VERSION ""

NS_ :

BS_:

BU_: TBox

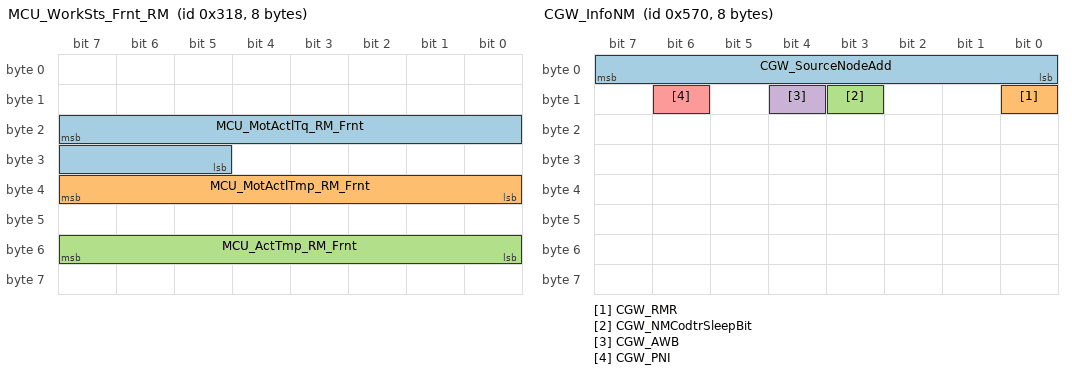
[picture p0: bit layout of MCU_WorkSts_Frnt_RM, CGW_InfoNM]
BO_ 792 MCU_WorkSts_Frnt_RM: 8 CGW
 SG_ MCU_MotActlTq_RM_Frnt : 23|11@0+ (0.5,-500) [-500|500] "Nm" TBox
 SG_ MCU_MotActlTmp_RM_Frnt : 39|8@0+ (1,-40) [-40|214] "degree C" TBox
 SG_ MCU_ActTmp_RM_Frnt : 55|8@0+ (1,-40) [-40|214] "degree C" TBox

BO_ 1392 CGW_InfoNM: 8 CGW
 SG_ CGW_SourceNodeAdd : 7|8@0+ (1,0) [112|112] "" TBox,HU,AMP
 SG_ CGW_RMR : 8|1@0+ (1,0) [0|1] "" TBox,HU,AMP
 SG_ CGW_NMCodtrSleepBit : 11|1@0+ (1,0) [0|1] "" TBox,HU,AMP
 SG_ CGW_AWB : 12|1@0+ (1,0) [0|1] "" TBox,HU,AMP
 SG_ CGW_PNI : 14|1@0+ (1,0) [0|1] "" TBox,HU,AMP

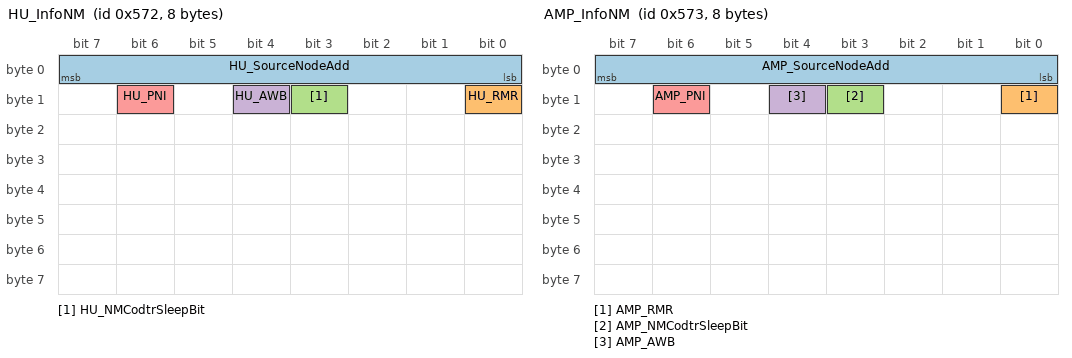
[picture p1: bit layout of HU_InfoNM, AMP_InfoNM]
BO_ 1394 HU_InfoNM: 8 HU
 SG_ HU_SourceNodeAdd : 7|8@0+ (1,0) [114|114] "" TBox,AMP,CGW
 SG_ HU_RMR : 8|1@0+ (1,0) [0|1] "" TBox,AMP,CGW
 SG_ HU_NMCodtrSleepBit : 11|1@0+ (1,0) [0|1] "" TBox,AMP,CGW
 SG_ HU_AWB : 12|1@0+ (1,0) [0|1] "" TBox,AMP,CGW
 SG_ HU_PNI : 14|1@0+ (1,0) [0|1] "" TBox,AMP,CGW

BO_ 1395 AMP_InfoNM: 8 AMP
 SG_ AMP_SourceNodeAdd : 7|8@0+ (1,0) [115|115] "" TBox,HU,CGW
 SG_ AMP_RMR : 8|1@0+ (1,0) [0|1] "" TBox,HU,CGW
 SG_ AMP_NMCodtrSleepBit : 11|1@0+ (1,0) [0|1] "" TBox,HU,CGW
 SG_ AMP_AWB : 12|1@0+ (1,0) [0|1] "" TBox,HU,CGW
 SG_ AMP_PNI : 14|1@0+ (1,0) [0|1] "" TBox,HU,CGW

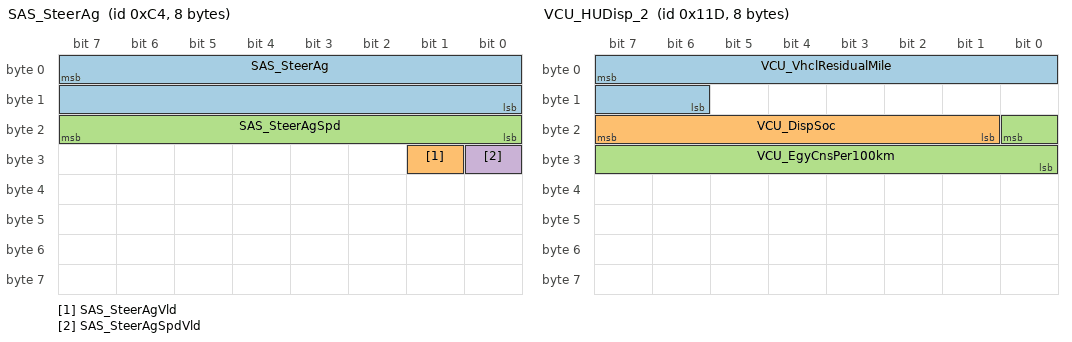
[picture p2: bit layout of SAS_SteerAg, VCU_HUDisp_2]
BO_ 196 SAS_SteerAg: 8 CGW
 SG_ SAS_SteerAg : 7|16@0+ (0.0625,-2048) [-720|720] "Deg" TBox,HU
 SG_ SAS_SteerAgVld : 25|1@0+ (1,0) [0|1] "" TBox,HU
 SG_ SAS_SteerAgSpd : 23|8@0+ (4,0) [0|1016] "Deg/s" TBox
 SG_ SAS_SteerAgSpdVld : 24|1@0+ (1,0) [0|1] "" TBox

BO_ 284 VCU_HUDisp_1: 8 CGW
 SG_ VCU_ChrgStsIndcr : 7|1@0+ (1,0) [0|1] "" TBox,HU,AMP
 SG_ VCU_ChrgConnectIndcr : 6|1@0+ (1,0) [0|1] "" TBox,HU

BO_ 285 VCU_HUDisp_2: 8 CGW
 SG_ VCU_VhclResidualMile : 7|10@0+ (1,0) [0|800] "km" TBox,HU
 SG_ VCU_DispSoc : 23|7@0+ (1,0) [0|100] "%" TBox,HU
 SG_ VCU_EgyCnsPer100km : 16|9@0+ (0.1,0) [0|30] "kwh/100km" TBox,HU

CM_ SG_ 1394 HU_SourceNodeAdd "Source Node Address
原节点地址";
CM_ SG_ 1394 HU_RMR "Repeat message request
重复报文请求";
CM_ SG_ 1394 HU_NMCodtrSleepBit "NM Coordinator Sleep Bit
网络管理协调睡眠指示位";
CM_ SG_ 1394 HU_AWB "Active wakeup bit
主动唤醒指示位";
CM_ SG_ 1394 HU_PNI "Partial netwark information bit 
局部网络指示位";
CM_ SG_ 1395 AMP_SourceNodeAdd "Source Node Address
原节点地址";
CM_ SG_ 1395 AMP_RMR "Repeat message request
重复报文请求";
CM_ SG_ 1395 AMP_NMCodtrSleepBit "NM Coordinator Sleep Bit
网络管理协调睡眠指示位";
CM_ SG_ 1395 AMP_AWB "Active wakeup bit
主动唤醒指示位";
CM_ SG_ 1395 AMP_PNI "Partial netwark information bit 
局部网络指示位";
CM_ SG_ 1392 CGW_SourceNodeAdd "Source Node Address
原节点地址";
CM_ SG_ 1392 CGW_RMR "Repeat message request
重复报文请求";
CM_ SG_ 1392 CGW_NMCodtrSleepBit "NM Coordinator Sleep Bit
网络管理协调睡眠指示位";
CM_ SG_ 1392 CGW_AWB "Active wakeup bit
主动唤醒指示位";
CM_ SG_ 1392 CGW_PNI "Partial netwark information bit 
局部网络指示位";
CM_ SG_ 284 VCU_ChrgStsIndcr "Charge status indicator
充电状态指示";
CM_ SG_ 284 VCU_ChrgConnectIndcr "Charge connect indicator
充电链接指示";
CM_ SG_ 285 VCU_VhclResidualMile "Vehicle residual mileage
剩余续驶里程";
CM_ SG_ 285 VCU_DispSoc "SOC used for display
动力电池剩余SOC";
CM_ SG_ 285 VCU_EgyCnsPer100km "Energy consume per 100km
平均百公里能耗";
CM_ SG_ 792 MCU_MotActlTq_RM_Frnt "Motor actual torque
电机实际扭矩";
CM_ SG_ 792 MCU_MotActlTmp_RM_Frnt "Actual temperature of motor
电机实际温度";
CM_ SG_ 792 MCU_ActTmp_RM_Frnt "MCU actual temperature
电机控制器实际温度";
CM_ SG_ 196 SAS_SteerAg "Steering Angle value
方向盘转向角";
CM_ SG_ 196 SAS_SteerAgVld "Steering Angle Valid Check
方向盘转向角有效位";
CM_ SG_ 196 SAS_SteerAgSpd "Steering  Angle Speed value
方向盘转角速度";
CM_ SG_ 196 SAS_SteerAgSpdVld "Steering Angle Speed valid Check
方向盘转向角速度有效位";

BA_DEF_ BO_  "NmMessage" ENUM "No","Yes";
BA_DEF_ BO_  "GenMsgSendType" ENUM  "Cycle","NoSendType","IfActive";
BA_DEF_ BO_  "GenMsgCycleTime" INT 0 0;
BA_DEF_ SG_  "GenSigSendType" ENUM  "Cycle","OnChange","OnWrite","IfActive","OnChangeWithRepetition","OnWriteWithRepetition","IfActiveWithRepetition";
BA_DEF_ SG_  "GenSigStartValue" INT 0 0;
BA_DEF_ BO_  "GenMsgCycleTimeFast" INT 0 0;
BA_DEF_ BO_  "GenMsgNrOfRepetition" INT 0 0;
BA_DEF_ BO_  "GenMsgDelayTime" INT 0 0;
BA_DEF_ BO_  "VFrameFormat" ENUM  "StandardCAN","ExtendedCAN","reserved","reserved","reserved","reserved","reserved","reserved","reserved","reserved","reserved","reserved","reserved","reserved","StandardCAN_FD","ExtendedCAN_FD";

BA_DEF_DEF_  "NmMessage" "No";
BA_DEF_DEF_  "GenMsgSendType" "Cycle";
BA_DEF_DEF_  "GenMsgCycleTime" 0;
BA_DEF_DEF_  "GenSigSendType" "Cycle";
BA_DEF_DEF_  "GenSigStartValue" 0;
BA_DEF_DEF_  "GenMsgCycleTimeFast" 0;
BA_DEF_DEF_  "GenMsgNrOfRepetition" 0;
BA_DEF_DEF_  "GenMsgDelayTime" 0;
BA_DEF_DEF_  "VFrameFormat" "StandardCAN";
BA_ "GenSigStartValue" SG_ 792 MCU_MotActlTq_RM_Frnt 1000;
BA_ "GenSigStartValue" SG_ 792 MCU_MotActlTmp_RM_Frnt 40;
BA_ "GenSigStartValue" SG_ 792 MCU_ActTmp_RM_Frnt 40;
BA_ "NmMessage" BO_ 1392 1;
BA_ "GenMsgCycleTime" BO_ 1392 500;
BA_ "GenMsgCycleTimeFast" BO_ 1392 10;
BA_ "GenMsgNrOfRepetition" BO_ 1392 5;
BA_ "GenSigSendType" SG_ 1392 CGW_SourceNodeAdd 6;
BA_ "GenSigStartValue" SG_ 1392 CGW_SourceNodeAdd 112;
BA_ "GenSigSendType" SG_ 1392 CGW_RMR 6;
BA_ "GenSigSendType" SG_ 1392 CGW_NMCodtrSleepBit 6;
BA_ "GenSigSendType" SG_ 1392 CGW_AWB 6;
BA_ "GenSigSendType" SG_ 1392 CGW_PNI 6;
BA_ "NmMessage" BO_ 1394 1;
BA_ "GenMsgCycleTime" BO_ 1394 500;
BA_ "GenMsgCycleTimeFast" BO_ 1394 10;
BA_ "GenMsgNrOfRepetition" BO_ 1394 5;
BA_ "GenSigSendType" SG_ 1394 HU_SourceNodeAdd 6;
BA_ "GenSigStartValue" SG_ 1394 HU_SourceNodeAdd 114;
BA_ "GenSigSendType" SG_ 1394 HU_RMR 6;
BA_ "GenSigSendType" SG_ 1394 HU_NMCodtrSleepBit 6;
BA_ "GenSigSendType" SG_ 1394 HU_AWB 6;
BA_ "GenSigSendType" SG_ 1394 HU_PNI 6;
BA_ "NmMessage" BO_ 1395 1;
BA_ "GenMsgCycleTime" BO_ 1395 500;
BA_ "GenMsgCycleTimeFast" BO_ 1395 10;
BA_ "GenMsgNrOfRepetition" BO_ 1395 5;
BA_ "GenSigSendType" SG_ 1395 AMP_SourceNodeAdd 6;
BA_ "GenSigStartValue" SG_ 1395 AMP_SourceNodeAdd 115;
BA_ "GenSigSendType" SG_ 1395 AMP_RMR 6;
BA_ "GenSigSendType" SG_ 1395 AMP_NMCodtrSleepBit 6;
BA_ "GenSigSendType" SG_ 1395 AMP_AWB 6;
BA_ "GenSigSendType" SG_ 1395 AMP_PNI 6;
BA_ "GenMsgCycleTime" BO_ 196 10;
BA_ "GenSigStartValue" SG_ 196 SAS_SteerAg 65535;
BA_ "GenSigStartValue" SG_ 196 SAS_SteerAgVld 1;
BA_ "GenSigStartValue" SG_ 196 SAS_SteerAgSpd 255;
BA_ "GenSigStartValue" SG_ 196 SAS_SteerAgSpdVld 1;
BA_ "GenMsgCycleTime" BO_ 284 100;
BA_ "GenMsgCycleTime" BO_ 285 100;
VAL_ 1394 HU_RMR 1 "Rpt Msg state req" 0 "Rpt Msg state not req" ;
VAL_ 1394 HU_NMCodtrSleepBit 1 "Synch Shutdwn Req by codtr" 0 "Synch Shutdwn NotReq by codtr" ;
VAL_ 1394 HU_AWB 1 "Active wakeup" 0 "Passive wakeup" ;
VAL_ 1394 HU_PNI 1 "Contain PNI" 0 "Contain no PNI" ;
VAL_ 1395 AMP_RMR 1 "Rpt Msg state req" 0 "Rpt Msg state not req" ;
VAL_ 1395 AMP_NMCodtrSleepBit 1 "Synch Shutdwn Req by codtr" 0 "Synch Shutdwn NotReq by codtr" ;
VAL_ 1395 AMP_AWB 1 "Active wakeup" 0 "Passive wakeup" ;
VAL_ 1395 AMP_PNI 1 "Contain PNI" 0 "Contain no PNI" ;
VAL_ 1392 CGW_RMR 1 "Rpt Msg state req" 0 "Rpt Msg state not req" ;
VAL_ 1392 CGW_NMCodtrSleepBit 1 "Synch Shutdwn Req by codtr" 0 "Synch Shutdwn NotReq by codtr" ;
VAL_ 1392 CGW_AWB 1 "Active wakeup" 0 "Passive wakeup" ;
VAL_ 1392 CGW_PNI 1 "Contain PNI" 0 "Contain no PNI" ;
VAL_ 284 VCU_ChrgStsIndcr 1 "True" 0 "False" ;
VAL_ 284 VCU_ChrgConnectIndcr 1 "True" 0 "False" ;
VAL_ 285 VCU_VhclResidualMile 1023 "Invalid" 1022 "Invalid" 1021 "Invalid" 1020 "Invalid" 1019 "Invalid" 1018 "Invalid" 1017 "Invalid" 1016 "Invalid" 1015 "Invalid" 1014 "Invalid" 1013 "Invalid" 1012 "Invalid" 1011 "Invalid" 1010 "Invalid" 1009 "Invalid" 1008 "Invalid" 1007 "Invalid" 1006 "Invalid" 1005 "Invalid" 1004 "Invalid" 1003 "Invalid" 1002 "Invalid" 1001 "Invalid" 1000 "Invalid" 999 "Invalid" 998 "Invalid" 997 "Invalid" 996 "Invalid" 995 "Invalid" 994 "Invalid" 993 "Invalid" 992 "Invalid" 991 "Invalid" 990 "Invalid" 989 "Invalid" 988 "Invalid" 987 "Invalid" 986 "Invalid" 985 "Invalid" 984 "Invalid" 983 "Invalid" 982 "Invalid" 981 "Invalid" 980 "Invalid" 979 "Invalid" 978 "Invalid" 977 "Invalid" 976 "Invalid" 975 "Invalid" 974 "Invalid" 973 "Invalid" 972 "Invalid" 971 "Invalid" 970 "Invalid" 969 "Invalid" 968 "Invalid" 967 "Invalid" 966 "Invalid" 965 "Invalid" 964 "Invalid" 963 "Invalid" 962 "Invalid" 961 "Invalid" 960 "Invalid" 959 "Invalid" 958 "Invalid" 957 "Invalid" 956 "Invalid" 955 "Invalid" 954 "Invalid" 953 "Invalid" 952 "Invalid" 951 "Invalid" 950 "Invalid" 949 "Invalid" 948 "Invalid" 947 "Invalid" 946 "Invalid" 945 "Invalid" 944 "Invalid" 943 "Invalid" 942 "Invalid" 941 "Invalid" 940 "Invalid" 939 "Invalid" 938 "Invalid" 937 "Invalid" 936 "Invalid" 935 "Invalid" 934 "Invalid" 933 "Invalid" 932 "Invalid" 931 "Invalid" 930 "Invalid" 929 "Invalid" 928 "Invalid" 927 "Invalid" 926 "Invalid" 925 "Invalid" 924 "Invalid" 923 "Invalid" 922 "Invalid" 921 "Invalid" 920 "Invalid" 919 "Invalid" 918 "Invalid" 917 "Invalid" 916 "Invalid" 915 "Invalid" 914 "Invalid" 913 "Invalid" 912 "Invalid" 911 "Invalid" 910 "Invalid" 909 "Invalid" 908 "Invalid" 907 "Invalid" 906 "Invalid" 905 "Invalid" 904 "Invalid" 903 "Invalid" 902 "Invalid" 901 "Invalid" 900 "Invalid" 899 "Invalid" 898 "Invalid" 897 "Invalid" 896 "Invalid" 895 "Invalid" 894 "Invalid" 893 "Invalid" 892 "Invalid" 891 "Invalid" 890 "Invalid" 889 "Invalid" 888 "Invalid" 887 "Invalid" 886 "Invalid" 885 "Invalid" 884 "Invalid" 883 "Invalid" 882 "Invalid" 881 "Invalid" 880 "Invalid" 879 "Invalid" 878 "Invalid" 877 "Invalid" 876 "Invalid" 875 "Invalid" 874 "Invalid" 873 "Invalid" 872 "Invalid" 871 "Invalid" 870 "Invalid" 869 "Invalid" 868 "Invalid" 867 "Invalid" 866 "Invalid" 865 "Invalid" 864 "Invalid" 863 "Invalid" 862 "Invalid" 861 "Invalid" 860 "Invalid" 859 "Invalid" 858 "Invalid" 857 "Invalid" 856 "Invalid" 855 "Invalid" 854 "Invalid" 853 "Invalid" 852 "Invalid" 851 "Invalid" 850 "Invalid" 849 "Invalid" 848 "Invalid" 847 "Invalid" 846 "Invalid" 845 "Invalid" 844 "Invalid" 843 "Invalid" 842 "Invalid" 841 "Invalid" 840 "Invalid" 839 "Invalid" 838 "Invalid" 837 "Invalid" 836 "Invalid" 835 "Invalid" 834 "Invalid" 833 "Invalid" 832 "Invalid" 831 "Invalid" 830 "Invalid" 829 "Invalid" 828 "Invalid" 827 "Invalid" 826 "Invalid" 825 "Invalid" 824 "Invalid" 823 "Invalid" 822 "Invalid" 821 "Invalid" 820 "Invalid" 819 "Invalid" 818 "Invalid" 817 "Invalid" 816 "Invalid" 815 "Invalid" 814 "Invalid" 813 "Invalid" 812 "Invalid" 811 "Invalid" 810 "Invalid" 809 "Invalid" 808 "Invalid" 807 "Invalid" 806 "Invalid" 805 "Invalid" 804 "Invalid" 803 "Invalid" 802 "Invalid" 801 "Invalid" ;
VAL_ 285 VCU_DispSoc 127 "Invalid" 126 "Invalid" 125 "Invalid" 124 "Invalid" 123 "Invalid" 122 "Invalid" 121 "Invalid" 120 "Invalid" 119 "Invalid" 118 "Invalid" 117 "Invalid" 116 "Invalid" 115 "Invalid" 114 "Invalid" 113 "Invalid" 112 "Invalid" 111 "Invalid" 110 "Invalid" 109 "Invalid" 108 "Invalid" 107 "Invalid" 106 "Invalid" 105 "Invalid" 104 "Invalid" 103 "Invalid" 102 "Invalid" 101 "Invalid" ;
VAL_ 285 VCU_EgyCnsPer100km 511 "Invalid" 510 "Invalid" 509 "Invalid" 508 "Invalid" 507 "Invalid" 506 "Invalid" 505 "Invalid" 504 "Invalid" 503 "Invalid" 502 "Invalid" 501 "Invalid" 500 "Invalid" 499 "Invalid" 498 "Invalid" 497 "Invalid" 496 "Invalid" 495 "Invalid" 494 "Invalid" 493 "Invalid" 492 "Invalid" 491 "Invalid" 490 "Invalid" 489 "Invalid" 488 "Invalid" 487 "Invalid" 486 "Invalid" 485 "Invalid" 484 "Invalid" 483 "Invalid" 482 "Invalid" 481 "Invalid" 480 "Invalid" 479 "Invalid" 478 "Invalid" 477 "Invalid" 476 "Invalid" 475 "Invalid" 474 "Invalid" 473 "Invalid" 472 "Invalid" 471 "Invalid" 470 "Invalid" 469 "Invalid" 468 "Invalid" 467 "Invalid" 466 "Invalid" 465 "Invalid" 464 "Invalid" 463 "Invalid" 462 "Invalid" 461 "Invalid" 460 "Invalid" 459 "Invalid" 458 "Invalid" 457 "Invalid" 456 "Invalid" 455 "Invalid" 454 "Invalid" 453 "Invalid" 452 "Invalid" 451 "Invalid" 450 "Invalid" 449 "Invalid" 448 "Invalid" 447 "Invalid" 446 "Invalid" 445 "Invalid" 444 "Invalid" 443 "Invalid" 442 "Invalid" 441 "Invalid" 440 "Invalid" 439 "Invalid" 438 "Invalid" 437 "Invalid" 436 "Invalid" 435 "Invalid" 434 "Invalid" 433 "Invalid" 432 "Invalid" 431 "Invalid" 430 "Invalid" 429 "Invalid" 428 "Invalid" 427 "Invalid" 426 "Invalid" 425 "Invalid" 424 "Invalid" 423 "Invalid" 422 "Invalid" 421 "Invalid" 420 "Invalid" 419 "Invalid" 418 "Invalid" 417 "Invalid" 416 "Invalid" 415 "Invalid" 414 "Invalid" 413 "Invalid" 412 "Invalid" 411 "Invalid" 410 "Invalid" 409 "Invalid" 408 "Invalid" 407 "Invalid" 406 "Invalid" 405 "Invalid" 404 "Invalid" 403 "Invalid" 402 "Invalid" 401 "Invalid" 400 "Invalid" 399 "Invalid" 398 "Invalid" 397 "Invalid" 396 "Invalid" 395 "Invalid" 394 "Invalid" 393 "Invalid" 392 "Invalid" 391 "Invalid" 390 "Invalid" 389 "Invalid" 388 "Invalid" 387 "Invalid" 386 "Invalid" 385 "Invalid" 384 "Invalid" 383 "Invalid" 382 "Invalid" 381 "Invalid" 380 "Invalid" 379 "Invalid" 378 "Invalid" 377 "Invalid" 376 "Invalid" 375 "Invalid" 374 "Invalid" 373 "Invalid" 372 "Invalid" 371 "Invalid" 370 "Invalid" 369 "Invalid" 368 "Invalid" 367 "Invalid" 366 "Invalid" 365 "Invalid" 364 "Invalid" 363 "Invalid" 362 "Invalid" 361 "Invalid" 360 "Invalid" 359 "Invalid" 358 "Invalid" 357 "Invalid" 356 "Invalid" 355 "Invalid" 354 "Invalid" 353 "Invalid" 352 "Invalid" 351 "Invalid" 350 "Invalid" 349 "Invalid" 348 "Invalid" 347 "Invalid" 346 "Invalid" 345 "Invalid" 344 "Invalid" 343 "Invalid" 342 "Invalid" 341 "Invalid" 340 "Invalid" 339 "Invalid" 338 "Invalid" 337 "Invalid" 336 "Invalid" 335 "Invalid" 334 "Invalid" 333 "Invalid" 332 "Invalid" 331 "Invalid" 330 "Invalid" 329 "Invalid" 328 "Invalid" 327 "Invalid" 326 "Invalid" 325 "Invalid" 324 "Invalid" 323 "Invalid" 322 "Invalid" 321 "Invalid" 320 "Invalid" 319 "Invalid" 318 "Invalid" 317 "Invalid" 316 "Invalid" 315 "Invalid" 314 "Invalid" 313 "Invalid" 312 "Invalid" 311 "Invalid" 310 "Invalid" 309 "Invalid" 308 "Invalid" 307 "Invalid" 306 "Invalid" 305 "Invalid" 304 "Invalid" 303 "Invalid" 302 "Invalid" 301 "Invalid" ;
VAL_ 792 MCU_MotActlTq_RM_Frnt 2047 "Invalid" 2046 "Invalid" 2045 "Invalid" 2044 "Invalid" 2043 "Invalid" 2042 "Invalid" 2041 "Invalid" 2040 "Invalid" 2039 "Invalid" 2038 "Invalid" 2037 "Invalid" 2036 "Invalid" 2035 "Invalid" 2034 "Invalid" 2033 "Invalid" 2032 "Invalid" 2031 "Invalid" 2030 "Invalid" 2029 "Invalid" 2028 "Invalid" 2027 "Invalid" 2026 "Invalid" 2025 "Invalid" 2024 "Invalid" 2023 "Invalid" 2022 "Invalid" 2021 "Invalid" 2020 "Invalid" 2019 "Invalid" 2018 "Invalid" 2017 "Invalid" 2016 "Invalid" 2015 "Invalid" 2014 "Invalid" 2013 "Invalid" 2012 "Invalid" 2011 "Invalid" 2010 "Invalid" 2009 "Invalid" 2008 "Invalid" 2007 "Invalid" 2006 "Invalid" 2005 "Invalid" 2004 "Invalid" 2003 "Invalid" 2002 "Invalid" 2001 "Invalid" ;
VAL_ 792 MCU_MotActlTmp_RM_Frnt 255 "Invalid" ;
VAL_ 792 MCU_ActTmp_RM_Frnt 255 "Invalid" ;
VAL_ 196 SAS_SteerAg 65535 "Invalid" ;
VAL_ 196 SAS_SteerAgVld 1 "Invalidity" 0 "Validity" ;
VAL_ 196 SAS_SteerAgSpd 255 "Invalid" ;
VAL_ 196 SAS_SteerAgSpdVld 1 "Invalidity" 0 "Validity" ;
